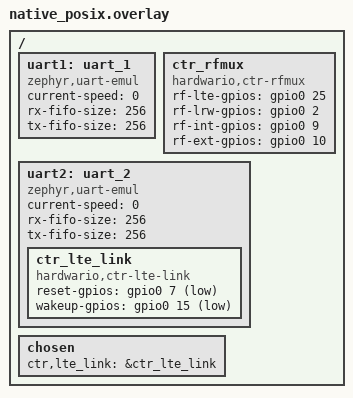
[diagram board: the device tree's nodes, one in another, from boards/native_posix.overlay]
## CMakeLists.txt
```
cmake_minimum_required(VERSION 3.20.0)

find_package(Zephyr REQUIRED HINTS $ENV{ZEPHYR_BASE})
project(test)

add_compile_definitions(CONFIG_CTR_RFMUX_LOG_LEVEL=4)
add_compile_definitions(CONFIG_CTR_LTE_LINK_LOG_LEVEL=3)

include_directories(${CMAKE_CURRENT_SOURCE_DIR}/../../../subsys/ctr_lte_v2)

target_sources(app PRIVATE src/mock_ctr_rfmux.c)
target_sources(app PRIVATE src/mock_ctr_lte_link.c)
target_sources(app PRIVATE src/mock_ctr_rtc.c)
target_sources(app PRIVATE src/mock_ctr_info.c)

target_sources_ifdef(CONFIG_TEST_FEATURE_PARSING app PRIVATE src/test_parse.c)
target_sources_ifdef(CONFIG_TEST_FEATURE_STACK app PRIVATE src/test_stack.c)
```

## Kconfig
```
#
# Copyright (c) 2023 HARDWARIO a.s.
#
# SPDX-License-Identifier: LicenseRef-HARDWARIO-5-Clause
#

menu "Test Features"

config TEST_FEATURE_PARSING
	bool "TEST_FEATURE_PARSING"
	default n

config TEST_FEATURE_STACK
	bool "TEST_FEATURE_PARSING"
	default n
	select CTR_LTE_V2_GNSS

config TEST_FEATURE_STACK_OVERRIDES_CONFIG
	bool "TEST_FEATURE_STACK"
	default n
	select CTR_LTE_V2_GNSS
	select TEST_FEATURE_STACK

config CTR_LTE_V2_DEFAULT_BANDS
	string "LTE Bands for CTR_LTE_V2"
	default "2,4,5,8,12,13,17,18,19,20,25,26,28,66" if TEST_FEATURE_STACK_OVERRIDES_CONFIG

config CTR_LTE_V2_DEFAULT_NETWORK
	string "Default Network for CTR_LTE_V2"
	default "23003" if TEST_FEATURE_STACK_OVERRIDES_CONFIG

config CTR_LTE_V2_DEFAULT_APN
	string "Default APN for CTR_LTE_V2"
	default "hardwario" if TEST_FEATURE_STACK_OVERRIDES_CONFIG

config CTR_LTE_V2_DEFAULT_ADDR
	string "Default Address for CTR_LTE_V2"
	default "46.101.214.168" if TEST_FEATURE_STACK_OVERRIDES_CONFIG

endmenu

#Include Zephyr's Kconfig
source "Kconfig"
```

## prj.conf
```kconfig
CONFIG_ZTEST=y
CONFIG_HEAP_MEM_POOL_SIZE=256
CONFIG_MAIN_STACK_SIZE=2048

CONFIG_LOG=y
CONFIG_LOG_FUNC_NAME_PREFIX_ERR=y
CONFIG_LOG_FUNC_NAME_PREFIX_WRN=y
CONFIG_LOG_FUNC_NAME_PREFIX_INF=y
CONFIG_LOG_FUNC_NAME_PREFIX_DBG=y

CONFIG_EVENTS=y

CONFIG_CTR_BUF=y
CONFIG_CTR_UTIL=y
CONFIG_CTR_CONFIG=y

CONFIG_CTR_LTE_V2=y
CONFIG_CTR_LTE_V2_LOG_LEVEL_DBG=y

CONFIG_SETTINGS=y

CONFIG_SHELL=y
CONFIG_SHELL_LOG_BACKEND=n
CONFIG_SHELL_BACKEND_SERIAL=y
CONFIG_SHELL_BACKEND_DUMMY=y
CONFIG_SHELL_CMD_BUFF_SIZE=90
CONFIG_SHELL_BACKEND_DUMMY_BUF_SIZE=4096

CONFIG_CBPRINTF_FP_SUPPORT=y

CONFIG_TEST_USERSPACE=y
CONFIG_GPIO=n
CONFIG_SERIAL=y
CONFIG_UART_NATIVE_PTY_0_ON_STDINOUT=y

CONFIG_HEAP_MEM_POOL_SIZE=8192

CONFIG_PM_DEVICE=y
CONFIG_REQUIRES_FULL_LIBC=y
CONFIG_RING_BUFFER=y
```

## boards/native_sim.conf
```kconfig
CONFIG_FLASH_SIMULATOR=y
CONFIG_FLASH=y
CONFIG_FLASH_MAP=y
```

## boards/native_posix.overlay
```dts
/ {

	uart1: uart_1 {
		compatible = "zephyr,uart-emul";
		status = "okay";
		current-speed = <0>;
		rx-fifo-size = <256>;
		tx-fifo-size = <256>;
	};

	ctr_rfmux: ctr_rfmux {
		compatible = "hardwario,ctr-rfmux";
		rf-lte-gpios = <&gpio0 25 GPIO_ACTIVE_HIGH>;
		rf-lrw-gpios = <&gpio0 2 GPIO_ACTIVE_HIGH>;
		rf-int-gpios = <&gpio0 9 GPIO_ACTIVE_HIGH>;
		rf-ext-gpios = <&gpio0 10 GPIO_ACTIVE_HIGH>;
	};

	uart2: uart_2 {
		compatible = "zephyr,uart-emul";
		status = "okay";
		current-speed = <0>;
		rx-fifo-size = <256>;
		tx-fifo-size = <256>;

		ctr_lte_link: ctr_lte_link {
			compatible = "hardwario,ctr-lte-link";
			status = "okay";
			reset-gpios = <&gpio0 7 (GPIO_ACTIVE_LOW | GPIO_OPEN_DRAIN)>;
			wakeup-gpios = <&gpio0 15 (GPIO_ACTIVE_LOW | GPIO_OPEN_DRAIN)>;
		};
	};
};

/ {
	chosen {
		ctr,lte_link = &ctr_lte_link;
	};
};
```

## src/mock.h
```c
#ifndef TESTS_SUBSYS_CTR_LTE_V2_SRC_MOCK_H_
#define TESTS_SUBSYS_CTR_LTE_V2_SRC_MOCK_H_

/* Zephyr includes */
#include <zephyr/kernel.h>

/* Standard includes */
#include <errno.h>
#include <stdarg.h>
#include <stdbool.h>
#include <stddef.h>
#include <stdint.h>
#include <stdio.h>
#include <string.h>

struct mock_link_item {
	const char *tx;
	const char *rx;
	const char *rx2;
	int delay_ms;
};

typedef char **list;

void mock_ctr_lte_link_start(struct mock_link_item *items, size_t count);

#endif
```

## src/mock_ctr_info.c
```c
#include <chester/ctr_info.h>

int ctr_info_get_vendor_name(char **vendor_name)
{
	static char name[] = "HARDWARIO";
	*vendor_name = name;
	return 0;
}

int ctr_info_get_product_name(char **product_name)
{
	static char name[] = "CHESTER-M";
	*product_name = name;
	return 0;
}

int ctr_info_get_hw_variant(char **hw_variant)
{
	static char variant[] = "CGLS";
	*hw_variant = variant;
	return 0;
}
int ctr_info_get_hw_revision(char **hw_revision)
{
	static char revision[] = "R3.2";
	*hw_revision = revision;
	return 0;
}

int ctr_info_get_fw_bundle(char **fw_bundle)
{
	static char bundle[] = "com.hardwario.mockup-app";
	*fw_bundle = bundle;
	return 0;
}

int ctr_info_get_fw_name(char **fw_name)
{
	static char name[] = "mockup-app";
	*fw_name = name;
	return 0;
}

int ctr_info_get_fw_version(char **fw_version)
{
	static char version[] = "v0.0.1";
	*fw_version = version;
	return 0;
}

int ctr_info_get_serial_number_uint32(uint32_t *serial_number)
{
	*serial_number = 2159017985;
	return 0;
}

int ctr_info_get_claim_token(char **claim_token)
{
	static char token[] = "98a8856ba6534bd5212176b22f3acbb3";
	*claim_token = token;
	return 0;
}

int ctr_info_get_ble_passkey(char **ble_passkey)
{
	static char passkey[] = "654123";
	*ble_passkey = passkey;
	return 0;
}

int ctr_info_get_product_family(enum ctr_info_product_family *product_family)
{
	*product_family = CTR_INFO_PRODUCT_FAMILY_CHESTER_M;
	return 0;
}
```

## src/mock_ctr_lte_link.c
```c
/*
 * Copyright (c) 2023 HARDWARIO a.s.
 *
 * SPDX-License-Identifier: LicenseRef-HARDWARIO-5-Clause
 */

#include "mock.h"
/* CHESTER includes */
#include <chester/drivers/ctr_lte_link.h>

/* Zephyr includes */
#include <zephyr/device.h>
#include <zephyr/devicetree.h>
#include <zephyr/kernel.h>
#include <zephyr/logging/log.h>
#include <zephyr/ztest.h>

/* Standard includes */
#include <errno.h>
#include <stdarg.h>
#include <stdbool.h>
#include <stddef.h>
#include <stdint.h>
#include <stdio.h>
#include <string.h>

#define DT_DRV_COMPAT hardwario_ctr_lte_link

LOG_MODULE_REGISTER(ctr_lte_link, LOG_LEVEL_INF);

#define RESET_DELAY   K_MSEC(100)
#define RESET_PAUSE   K_SECONDS(3)
#define WAKE_UP_DELAY K_MSEC(100)
#define WAKE_UP_PAUSE K_MSEC(100)
#define TX_GUARD_TIME K_MSEC(10)

#define TX_LINE_SUFFIX "\r\n"

#define TX_LINE_BUF_SIZE 1024
#define RX_LINE_BUF_SIZE 1024
#define RX_HEAP_MEM_SIZE 4096
#define RX_PIPE_BUF_SIZE 512
#define STACK_SIZE       1024
#define WORKQ_PRIORITY   K_PRIO_COOP(7)

struct ctr_lte_link_data {
	bool enabled;
	struct k_mutex lock;
	atomic_t in_dialog;
	atomic_t in_data_mode;
	atomic_t stop_request;
	char rx_line_buf[RX_LINE_BUF_SIZE];
	char tx_line_buf[TX_LINE_BUF_SIZE];
	const struct device *dev;
	ctr_lte_link_user_cb user_cb;
	void *user_data;
	struct k_work event_dispatch_work;
	struct k_work_delayable urc_dispatch_work;

	struct k_work_q workq;
	K_KERNEL_STACK_MEMBER(workq_stack, STACK_SIZE);
	struct k_fifo rx_fifo;
	struct k_heap rx_heap;
	uint8_t rx_heap_mem[RX_HEAP_MEM_SIZE];
	k_timepoint_t tx_timepoint;

	struct mock_link_item *items;
	size_t items_count;
	size_t items_index;

	const char *pending_rx_data;
	size_t pending_rx_data_len;
};

static inline struct ctr_lte_link_data *get_data(const struct device *dev)
{
	return dev->data;
}

static int ctr_lte_link_set_callback_(const struct device *dev, ctr_lte_link_user_cb user_cb,
				      void *user_data)
{

	k_mutex_lock(&get_data(dev)->lock, K_FOREVER);

	get_data(dev)->user_cb = user_cb;
	get_data(dev)->user_data = user_data;

	k_mutex_unlock(&get_data(dev)->lock);

	return 0;
}

static void ctr_lte_link_lock_(const struct device *dev)
{
	LOG_DBG("Lock");
	k_mutex_lock(&get_data(dev)->lock, K_FOREVER);
}

static void ctr_lte_link_unlock_(const struct device *dev)
{
	LOG_DBG("Unlock");
	k_mutex_unlock(&get_data(dev)->lock);
}

static int ctr_lte_link_reset_(const struct device *dev)
{

	LOG_DBG("Reset");
	k_sleep(RESET_DELAY);
	// k_sleep(RESET_PAUSE);
	return 0;
}

static int rx(const struct device *dev, const char line[])
{
	size_t len = strlen(line);

	struct ctr_lte_link_data *data = get_data(dev);

	char *p = k_heap_alloc(&data->rx_heap, len + 1, K_NO_WAIT);
	if (!p) {
		LOG_ERR("Call `k_heap_alloc` failed");
		if (data->user_cb) {
			data->user_cb(data->dev, CTR_LTE_LINK_EVENT_RX_LOSS, data->user_data);
		}

		return -ENOMEM;
	}

	LOG_DBG("Allocated from heap: %p - %u byte(s)", (void *)p, len + 1);

	strcpy(p, line);

	int ret = k_fifo_alloc_put(&data->rx_fifo, p);
	if (ret) {
		LOG_ERR("Call `k_fifo_alloc_put` failed: %d", ret);
		k_heap_free(&data->rx_heap, p);
		LOG_DBG("Released from heap: %p", (void *)p);
		return -ENOMEM;
	}

	if (data->user_cb && !atomic_get(&data->in_dialog)) {
		k_work_submit_to_queue(&data->workq, &data->event_dispatch_work);
	}

	return 0;
}

static void event_dispatch_work_handler(struct k_work *work)
{
	struct ctr_lte_link_data *const data =
		CONTAINER_OF(work, struct ctr_lte_link_data, event_dispatch_work);

	if (data->user_cb) {
		data->user_cb(data->dev, CTR_LTE_LINK_EVENT_RX_LINE, data->user_data);
	}
}

static void urc_dispatch_work_handler(struct k_work *work)
{
	struct ctr_lte_link_data *const data = CONTAINER_OF(
		(struct k_work_delayable *)work, struct ctr_lte_link_data, urc_dispatch_work);

	if (data->items_index < data->items_count) {
		const struct mock_link_item *item = &data->items[data->items_index];
		if (item->tx == NULL) {
			data->items_index++;
			if (item->rx) {
				rx(data->dev, item->rx);

				/* If URC starts with #XRECV:, store rx2 as pending data */
				if (strncmp(item->rx, "#XRECV:", 7) == 0 && item->rx2) {
					int expected_len = 0;
					sscanf(item->rx + 7, " %d", &expected_len);
					zassert_equal(
						(size_t)expected_len, strlen(item->rx2),
						"XRECV len mismatch: header says %d, data is %zu",
						expected_len, strlen(item->rx2));

					data->pending_rx_data = item->rx2;
					data->pending_rx_data_len = strlen(item->rx2);
				}
			}
			if (data->items_index < data->items_count) {
				item = &data->items[data->items_index];
				if (item->tx == NULL) {
					k_work_schedule(&data->urc_dispatch_work,
							K_MSEC(item->delay_ms));
				}
			}
		}
	}
}

static int ctr_lte_link_wake_up_(const struct device *dev)
{

	LOG_INF("Wake up");
	k_sleep(WAKE_UP_DELAY);
	// k_sleep(WAKE_UP_PAUSE);
	rx(dev, "Ready");
	return 0;
}

static int ctr_lte_link_enable_uart_(const struct device *dev)
{

	LOG_DBG("Enable UART");

	k_mutex_lock(&get_data(dev)->lock, K_FOREVER);

	if (get_data(dev)->enabled) {
		k_mutex_unlock(&get_data(dev)->lock);
		return 0;
	}

	atomic_set(&get_data(dev)->in_dialog, false);
	atomic_set(&get_data(dev)->in_data_mode, false);
	atomic_set(&get_data(dev)->stop_request, false);

	get_data(dev)->enabled = true;

	k_mutex_unlock(&get_data(dev)->lock);

	return 0;
}

static int ctr_lte_link_disable_uart_(const struct device *dev)
{

	LOG_DBG("Disable UART");

	k_mutex_lock(&get_data(dev)->lock, K_FOREVER);

	if (!get_data(dev)->enabled) {
		k_mutex_unlock(&get_data(dev)->lock);
		return 0;
	}

	get_data(dev)->enabled = false;

	k_mutex_unlock(&get_data(dev)->lock);

	return 0;
}

static int ctr_lte_link_enter_data_mode_(const struct device *dev)
{
	LOG_DBG("Enter data mode");

	k_mutex_lock(&get_data(dev)->lock, K_FOREVER);

	if (!get_data(dev)->enabled) {
		k_mutex_unlock(&get_data(dev)->lock);
		return -EBUSY;
	}

	atomic_set(&get_data(dev)->in_data_mode, true);

	k_mutex_unlock(&get_data(dev)->lock);

	return 0;
}

static int ctr_lte_link_exit_data_mode_(const struct device *dev)
{
	LOG_DBG("Exit data mode");

	k_mutex_lock(&get_data(dev)->lock, K_FOREVER);

	if (!get_data(dev)->enabled) {
		k_mutex_unlock(&get_data(dev)->lock);
		return -EBUSY;
	}

	atomic_set(&get_data(dev)->in_data_mode, false);

	k_mutex_unlock(&get_data(dev)->lock);

	return 0;
}

static int ctr_lte_link_enter_dialog_(const struct device *dev)
{
	LOG_DBG("Enter dialog");

	k_mutex_lock(&get_data(dev)->lock, K_FOREVER);

	if (!get_data(dev)->enabled) {
		k_mutex_unlock(&get_data(dev)->lock);
		return -EBUSY;
	}

	atomic_set(&get_data(dev)->in_dialog, true);

	k_mutex_unlock(&get_data(dev)->lock);

	return 0;
}

static int ctr_lte_link_exit_dialog_(const struct device *dev)
{
	LOG_DBG("Exit dialog");

	k_mutex_lock(&get_data(dev)->lock, K_FOREVER);

	if (!get_data(dev)->enabled) {
		k_mutex_unlock(&get_data(dev)->lock);
		return -EBUSY;
	}

	atomic_set(&get_data(dev)->in_dialog, false);

	k_mutex_unlock(&get_data(dev)->lock);

	return 0;
}

static int ctr_lte_link_send_line_(const struct device *dev, k_timeout_t timeout,
				   const char *format, va_list ap)
{

	struct ctr_lte_link_data *data = get_data(dev);

	k_mutex_lock(&data->lock, K_FOREVER);

	if (!data->enabled) {
		k_mutex_unlock(&data->lock);
		return -EBUSY;
	}

	if (data->in_data_mode) {
		k_mutex_unlock(&data->lock);
		return -EPERM;
	}

	// if (!sys_timepoint_expired(data->tx_timepoint)) {
	// 	k_sleep(sys_timepoint_timeout(data->tx_timepoint));
	// }

	size_t size = sizeof(data->tx_line_buf) - strlen(TX_LINE_SUFFIX);

	int ret = vsnprintf(data->tx_line_buf, size, format, ap);
	if (ret < 0) {
		LOG_ERR("Call `vsnprintf` failed: %d", ret);
		k_mutex_unlock(&data->lock);
		return -EINVAL;
	} else if (ret >= size) {
		LOG_ERR("Buffer too small");
		k_mutex_unlock(&data->lock);
		return -ENOBUFS;
	}

	LOG_INF("Send line: %s", data->tx_line_buf);

	// strcat(data->tx_line_buf, TX_LINE_SUFFIX);

	if (data->items_index < data->items_count) {
		const struct mock_link_item *item = &data->items[data->items_index];
		if (item->tx) {
			zassert_true(strcmp(data->tx_line_buf, item->tx) == 0,
				     "unexpected TX line: get %s, expected %s", data->tx_line_buf,
				     item->tx);

			data->items_index++;
			if (item->rx) {
				rx(dev, item->rx);
			}
			if (item->rx2) {
				rx(dev, item->rx2);
			}
			if (data->items_index < data->items_count) {
				item = &data->items[data->items_index];
				if (item->tx == NULL) {
					k_work_schedule(&data->urc_dispatch_work,
							K_MSEC(item->delay_ms));
				}
			}
		} else {
			LOG_ERR("Missing TX item %d", data->items_index);
		}
	}

	// if (strcmp(data->tx_line_buf, "AT") == 0) {
	// 	rx(dev, "OK");
	// }
	// if (strcmp(data->tx_line_buf, "AT+CGSN=1") == 0) {
	// 	rx(dev, "+CGSN: \"351358815178345\"");
	// 	rx(dev, "OK");
	// }

	// data->tx_timepoint = sys_timepoint_calc(TX_GUARD_TIME);

	k_mutex_unlock(&data->lock);

	return 0;
}

static int ctr_lte_link_recv_line_(const struct device *dev, k_timeout_t timeout, char **line)
{
	k_mutex_lock(&get_data(dev)->lock, K_FOREVER);

	if (get_data(dev)->in_data_mode) {
		k_mutex_unlock(&get_data(dev)->lock);
		return -EPERM;
	}

	*line = k_fifo_get(&get_data(dev)->rx_fifo, timeout);
	if (*line) {
		LOG_INF("Receive line: %s", *line);
	}

	k_mutex_unlock(&get_data(dev)->lock);

	return 0;
}

static int ctr_lte_link_free_line_(const struct device *dev, char *line)
{

	k_mutex_lock(&get_data(dev)->lock, K_FOREVER);

	k_heap_free(&get_data(dev)->rx_heap, line);
	LOG_DBG("Released from heap: %p", (void *)line);

	k_mutex_unlock(&get_data(dev)->lock);

	return 0;
}

static int ctr_lte_link_send_data_(const struct device *dev, k_timeout_t timeout, const void *buf,
				   size_t len)
{

	k_mutex_lock(&get_data(dev)->lock, K_FOREVER);

	if (!get_data(dev)->enabled) {
		k_mutex_unlock(&get_data(dev)->lock);
		return -EBUSY;
	}

	if (!get_data(dev)->in_data_mode) {
		k_mutex_unlock(&get_data(dev)->lock);
		return -EPERM;
	}

	k_mutex_unlock(&get_data(dev)->lock);

	return 0;
}

static int ctr_lte_link_recv_data_(const struct device *dev, k_timeout_t timeout, void *buf,
				   size_t size, size_t *len)
{
	struct ctr_lte_link_data *data = get_data(dev);

	LOG_INF("size: %d pending: %d", size, data->pending_rx_data_len);

	k_mutex_lock(&data->lock, K_FOREVER);

	if (!data->enabled) {
		k_mutex_unlock(&data->lock);
		return -EBUSY;
	}

	if (!data->in_data_mode) {
		k_mutex_unlock(&data->lock);
		return -EPERM;
	}

	*len = 0;

	if (data->pending_rx_data && data->pending_rx_data_len > 0) {
		size_t copy_len = data->pending_rx_data_len;
		if (copy_len > size) {
			copy_len = size;
		}
		memcpy(buf, data->pending_rx_data, copy_len);
		*len = copy_len;

		data->pending_rx_data = NULL;
		data->pending_rx_data_len = 0;
		rx(dev, "OK"); // Simulate OK after XRECV data is read
	}

	k_mutex_unlock(&data->lock);

	return 0;
}

static int ctr_lte_link_drv_init(const struct device *dev)
{
	struct ctr_lte_link_data *data = get_data(dev);
	k_mutex_init(&data->lock);
	k_fifo_init(&data->rx_fifo);
	k_heap_init(&data->rx_heap, data->rx_heap_mem, RX_HEAP_MEM_SIZE);

	struct k_work_queue_config cfg = {
		.name = "ctr_lte_link_drv_workq",
	};

	k_work_queue_start(&data->workq, data->workq_stack,
			   K_THREAD_STACK_SIZEOF(data->workq_stack), WORKQ_PRIORITY, &cfg);

	k_work_init(&data->event_dispatch_work, event_dispatch_work_handler);
	k_work_init_delayable(&data->urc_dispatch_work, urc_dispatch_work_handler);
	return 0;
}

static const struct ctr_lte_link_driver_api ctr_lte_link_driver_api = {
	.set_callback = ctr_lte_link_set_callback_,
	.lock = ctr_lte_link_lock_,
	.unlock = ctr_lte_link_unlock_,
	.reset = ctr_lte_link_reset_,
	.wake_up = ctr_lte_link_wake_up_,
	.enable_uart = ctr_lte_link_enable_uart_,
	.disable_uart = ctr_lte_link_disable_uart_,
	.enter_dialog = ctr_lte_link_enter_dialog_,
	.exit_dialog = ctr_lte_link_exit_dialog_,
	.enter_data_mode = ctr_lte_link_enter_data_mode_,
	.exit_data_mode = ctr_lte_link_exit_data_mode_,
	.send_line = ctr_lte_link_send_line_,
	.recv_line = ctr_lte_link_recv_line_,
	.free_line = ctr_lte_link_free_line_,
	.send_data = ctr_lte_link_send_data_,
	.recv_data = ctr_lte_link_recv_data_,
};

#define CTR_LTE_LINK_INIT(n)                                                                       \
	static struct ctr_lte_link_data inst_##n##_data = {                                        \
		.dev = DEVICE_DT_INST_GET(n),                                                      \
	};                                                                                         \
	DEVICE_DT_INST_DEFINE(n, ctr_lte_link_drv_init, NULL, &inst_##n##_data, NULL, POST_KERNEL, \
			      CONFIG_SERIAL_INIT_PRIORITY, &ctr_lte_link_driver_api);

DT_INST_FOREACH_STATUS_OKAY(CTR_LTE_LINK_INIT)

void mock_ctr_lte_link_start(struct mock_link_item *items, size_t count)
{
	LOG_INF("Mock CTR LTE LINK start");

	const struct device *dev = DEVICE_DT_INST_GET(0);

	if (!device_is_ready(dev)) {
		LOG_ERR("Device is not ready");
		return;
	}

	struct ctr_lte_link_data *data = get_data(DEVICE_DT_INST_GET(0));

	k_mutex_lock(&data->lock, K_FOREVER);

	data->items = items;
	data->items_count = count;
	data->items_index = 0;

	k_mutex_unlock(&data->lock);
}
```

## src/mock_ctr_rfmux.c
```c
/*
 * Copyright (c) 2023 HARDWARIO a.s.
 *
 * SPDX-License-Identifier: LicenseRef-HARDWARIO-5-Clause
 */

/* CHESTER includes */
#include <chester/drivers/ctr_rfmux.h>

/* Zephyr includes */
#include <zephyr/devicetree.h>
#include <zephyr/drivers/gpio.h>
#include <zephyr/kernel.h>
#include <zephyr/logging/log.h>

/* Standard includes */
#include <stdbool.h>
#include <stddef.h>

#define DT_DRV_COMPAT hardwario_ctr_rfmux

LOG_MODULE_REGISTER(ctr_rfmux, CONFIG_CTR_RFMUX_LOG_LEVEL);

struct ctr_rfmux_data {
	const struct device *dev;
	struct k_sem lock;
	bool is_acquired;
};

static inline struct ctr_rfmux_data *get_data(const struct device *dev)
{
	return dev->data;
}

static int ctr_rfmux_acquire_(const struct device *dev)
{
	if (k_is_in_isr()) {
		return -EWOULDBLOCK;
	}

	k_sem_take(&get_data(dev)->lock, K_FOREVER);

	if (get_data(dev)->is_acquired) {
		k_sem_give(&get_data(dev)->lock);
		return -EBUSY;
	}

	get_data(dev)->is_acquired = true;

	k_sem_give(&get_data(dev)->lock);

	return 0;
}

static int ctr_rfmux_release_(const struct device *dev)
{
	if (k_is_in_isr()) {
		return -EWOULDBLOCK;
	}

	k_sem_take(&get_data(dev)->lock, K_FOREVER);

	if (!get_data(dev)->is_acquired) {
		k_sem_give(&get_data(dev)->lock);
		return -EACCES;
	}

	get_data(dev)->is_acquired = false;

	k_sem_give(&get_data(dev)->lock);

	return 0;
}

static int ctr_rfmux_set_interface_(const struct device *dev, enum ctr_rfmux_interface interface)
{

	if (k_is_in_isr()) {
		return -EWOULDBLOCK;
	}

	k_sem_take(&get_data(dev)->lock, K_FOREVER);

	if (!get_data(dev)->is_acquired) {
		k_sem_give(&get_data(dev)->lock);
		return -EACCES;
	}

	k_sem_give(&get_data(dev)->lock);

	return 0;
}

static int ctr_rfmux_set_antenna_(const struct device *dev, enum ctr_rfmux_antenna antenna)
{

	if (k_is_in_isr()) {
		return -EWOULDBLOCK;
	}

	k_sem_take(&get_data(dev)->lock, K_FOREVER);

	if (!get_data(dev)->is_acquired) {
		k_sem_give(&get_data(dev)->lock);
		return -EACCES;
	}

	k_sem_give(&get_data(dev)->lock);

	return 0;
}

static int ctr_rfmux_init(const struct device *dev)
{

	k_sem_give(&get_data(dev)->lock);

	return 0;
}

static const struct ctr_rfmux_driver_api ctr_rfmux_driver_api = {
	.acquire = ctr_rfmux_acquire_,
	.release = ctr_rfmux_release_,
	.set_interface = ctr_rfmux_set_interface_,
	.set_antenna = ctr_rfmux_set_antenna_,
};

#define CTR_RFMUX_INIT(n)                                                                          \
	static struct ctr_rfmux_data inst_##n##_data = {                                           \
		.dev = DEVICE_DT_INST_GET(n),                                                      \
		.lock = Z_SEM_INITIALIZER(inst_##n##_data.lock, 0, 1),                             \
	};                                                                                         \
	DEVICE_DT_INST_DEFINE(n, ctr_rfmux_init, NULL, &inst_##n##_data, NULL, POST_KERNEL,        \
			      CONFIG_KERNEL_INIT_PRIORITY_DEVICE, &ctr_rfmux_driver_api);

DT_INST_FOREACH_STATUS_OKAY(CTR_RFMUX_INIT)
```

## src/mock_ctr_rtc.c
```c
#include <chester/ctr_rtc.h>

static int64_t m_ts = 0;

int ctr_rtc_set_ts(int64_t ts)
{
	m_ts = ts;
	return 0;
}

int ctr_rtc_get_ts(int64_t *ts)
{
	*ts = m_ts;
	return 0;
}
```

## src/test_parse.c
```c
/** @file
 *  @brief ctr_lte_v2 parse test suite
 *
 */

/* west twister -p native_sim -c -i -j 1 --testsuite-root . -vv */

#include <zephyr/kernel.h>
#include <zephyr/ztest.h>

#include <chester/ctr_buf.h>
#include <ctr_lte_v2_parse.h>

ZTEST(parser, test_xsocket_set)
{
	struct xsocket_set_param param;
	int ret = ctr_lte_v2_parse_xsocket_set("0,2,17", &param);

	zassert_ok(ret, "ctr_lte_v2_parse_xsocket_set failed");
	zassert_equal(param.handle, 0, "handle not equal");
	zassert_equal(param.type, 2, "type not equal");
	zassert_equal(param.protocol, 17, "protocol not equal");
}

ZTEST(parser, test_xsocket_get)
{
	struct xsocket_get_param param;
	int ret = ctr_lte_v2_parse_xsocket_get("0,1,0,2,0", &param);

	zassert_ok(ret, "ctr_lte_v2_parse_xsocket_set failed");
	zassert_equal(param.handle, 0, "handle not equal");
	zassert_equal(param.family, 1, "family not equal");
	zassert_equal(param.role, 0, "role not equal");
	zassert_equal(param.type, 2, "type not equal");
	zassert_equal(param.cid, 0, "cid not equal");
}

ZTEST(parser, test_urc_cereg_5)
{
	struct ctr_lte_v2_cereg_param param;
	int ret = ctr_lte_v2_parse_urc_cereg(
		"5,\"AF66\",\"009DE067\",9,,,\"00000000\",\"00111000\"", &param);

	zassert_ok(ret, "ctr_lte_v2_parse_urc_cereg failed");
	zassert_equal(param.valid, true, "param.valid not true");
	zassert_equal(param.stat, 5, "param.stat not equal");
	zassert_true(strcmp(param.tac, "AF66") == 0, "param.tac not equal");
	zassert_equal(param.cid, 0x009DE067, "param.cid not equal");
	zassert_equal(param.act, 9, "param.act not equal");
	zassert_equal(param.cause_type, 0, "param.cause_type not equal");
	zassert_equal(param.reject_cause, 0, "param.reject_cause not equal");
	zassert_equal(param.active_time, 0, "param.active_time not equal");
	zassert_equal(param.periodic_tau_ext, 86400, "param.periodic_tau_ext not equal");
}

ZTEST(parser, test_urc_cereg_5_active_time)
{
	struct ctr_lte_v2_cereg_param param;
	int ret = ctr_lte_v2_parse_urc_cereg(
		"5,\"AF66\",\"009DE067\",9,,,\"00000101\",\"00111000\"", &param);

	zassert_ok(ret, "ctr_lte_v2_parse_urc_cereg failed");
	zassert_equal(param.valid, true, "param.valid not true");
	zassert_equal(param.stat, 5, "param.stat not equal");
	zassert_true(strcmp(param.tac, "AF66") == 0, "param.tac not equal");
	zassert_equal(param.cid, 0x009DE067, "param.cid not equal");
	zassert_equal(param.act, 9, "param.act not equal");
	zassert_equal(param.cause_type, 0, "param.cause_type not equal");
	zassert_equal(param.reject_cause, 0, "param.reject_cause not equal");
	zassert_equal(param.active_time, 10, "param.active_time not equal");
	zassert_equal(param.periodic_tau_ext, 86400, "param.periodic_tau_ext not equal");
}

ZTEST(parser, test_urc_cereg_5_psm_disabled)
{
	struct ctr_lte_v2_cereg_param param;
	int ret = ctr_lte_v2_parse_urc_cereg(
		"5,\"3866\",\"074FEB0C\",7,,,\"11100000\",\"11100000\"", &param);

	zassert_ok(ret, "ctr_lte_v2_parse_urc_cereg failed");
	zassert_equal(param.valid, true, "param.valid not true");
	zassert_equal(param.stat, 5, "param.stat not equal");
	zassert_true(strcmp(param.tac, "3866") == 0, "param.tac not equal");
	zassert_equal(param.cid, 0x074FEB0C, "param.cid not equal");
	zassert_equal(param.act, 7, "param.act not equal");
	zassert_equal(param.cause_type, 0, "param.cause_type not equal");
	zassert_equal(param.reject_cause, 0, "param.reject_cause not equal");
	zassert_equal(param.active_time, -1, "param.active_time not equal");
	zassert_equal(param.periodic_tau_ext, -1, "param.periodic_tau_ext not equal");
}

ZTEST(parser, test_urc_cereg_2)
{
	struct ctr_lte_v2_cereg_param param;
	int ret = ctr_lte_v2_parse_urc_cereg("2,\"B4DC\",\"000AE520\",9", &param);

	zassert_ok(ret, "ctr_lte_v2_parse_urc_cereg failed");
	zassert_equal(param.valid, true, "param.valid not true");
	zassert_equal(param.stat, 2, "param.stat not equal");
	zassert_true(strcmp(param.tac, "B4DC") == 0, "param.tac not equal");
	zassert_equal(param.cid, 0x000AE520, "param.cid not equal");
	zassert_equal(param.act, 9, "param.act not equal");
}

ZTEST(parser, test_urc_cereg_2_empty)
{
	struct ctr_lte_v2_cereg_param param;
	int ret = ctr_lte_v2_parse_urc_cereg("2", &param);

	zassert_ok(ret, "ctr_lte_v2_parse_urc_cereg failed");
	zassert_equal(param.valid, true, "param.valid not true");
	zassert_equal(param.stat, 2, "param.stat not equal");
	zassert_true(strcmp(param.tac, "") == 0, "param.tac not equal");
	zassert_equal(param.cid, 0, "param.cid not equal");
	zassert_equal(param.act, 0, "param.act not equal");
}

ZTEST(parser, test_urc_cereg_4)
{
	struct ctr_lte_v2_cereg_param param;
	int ret = ctr_lte_v2_parse_urc_cereg("4", &param);

	zassert_ok(ret, "ctr_lte_v2_parse_urc_cereg failed");
	zassert_equal(param.valid, true, "param.valid not true");
	zassert_equal(param.stat, 4, "param.stat not equal");
	zassert_true(strcmp(param.tac, "") == 0, "param.tac not equal");
	zassert_equal(param.cid, 0, "param.cid not equal");
	zassert_equal(param.act, 0, "param.act not equal");
}

ZTEST(parser, test_urc_xmodemsleep_1_89999825)
{
	int p1, p2;
	int ret = ctr_lte_v2_parse_urc_xmodemsleep("1,89999825", &p1, &p2);

	zassert_ok(ret, "ctr_lte_v2_parse_urc_xmodemsleep failed");
	zassert_equal(p1, 1, "p1 not equal");
	zassert_equal(p2, 89999825, "p2 not equal");
}

ZTEST(parser, test_urc_xmodemsleep_1_0)
{
	int p1, p2;
	int ret = ctr_lte_v2_parse_urc_xmodemsleep("1,0", &p1, &p2);

	zassert_ok(ret, "ctr_lte_v2_parse_urc_xmodemsleep failed");
	zassert_equal(p1, 1, "p1 not equal");
	zassert_equal(p2, 0, "p2 not equal");
}

ZTEST(parser, test_urc_xmodemsleep_4_0)
{
	int p1, p2;
	int ret = ctr_lte_v2_parse_urc_xmodemsleep("4,0", &p1, &p2);

	zassert_ok(ret, "ctr_lte_v2_parse_urc_xmodemsleep failed");
	zassert_equal(p1, 4, "p1 not equal");
	zassert_equal(p2, 0, "p2 not equal");
}

ZTEST(parser, test_urc_xmodemsleep_4)
{
	int p1, p2;
	int ret = ctr_lte_v2_parse_urc_xmodemsleep("4", &p1, &p2);

	zassert_ok(ret, "ctr_lte_v2_parse_urc_xmodemsleep failed");
	zassert_equal(p1, 4, "p1 not equal");
	zassert_equal(p2, 0, "p2 not equal");
}

ZTEST(parser, test_coneval)
{

	struct ctr_lte_v2_conn_param param;
	int ret = ctr_lte_v2_parse_coneval(
		"0,1,7,68,29,47,\"000AE520\",\"23003\",135,6447,20,0,0,14,2,1,99", &param);

	zassert_ok(ret, "ctr_lte_v2_parse_coneval failed");
	zassert_equal(param.valid, true, "param.valid not true");
	zassert_equal(param.result, 0, "param.result not equal"); // success
	zassert_equal(param.eest, 7, "param.eest not equal");     // energy_estimate
	zassert_equal(param.ecl, 0, "param.ecl not equal");
	zassert_equal(param.rsrp, -72, "param.rsrp not equal");
	zassert_equal(param.rsrq, -5, "param.rsrq not equal");
	zassert_equal(param.snr, 23, "param.snr not equal");
	zassert_equal(param.plmn, 23003, "param.plmn not equal");
	zassert_equal(param.cid, 0x000AE520, "param.cid not equal");
	zassert_equal(param.band, 20, "param.band not equal");
	zassert_equal(param.earfcn, 6447, "param.earfcn not equal");
}

ZTEST(parser, test_urc_xgps)
{
	struct ctr_lte_v2_gnss_update update;

	char line[] = "49.256683,17.699627,292.599670,5.468742,0.165512,73.682823,\"2024-06-27 "
		      "16:06:52\"";
	int ret = ctr_lte_v2_parse_urc_xgps(line, &update);

	zassert_ok(ret, "ctr_lte_v2_parse_urc_xgps failed");
	zassert_within((double)update.latitude, 49.256683, 0.000001, "update.latitude not equal");
	zassert_within((double)update.longitude, 17.699627, 0.000001, "update.longitude not equal");
	zassert_within((double)update.altitude, 292.599670, 0.000001, "update.altitude not equal");
	zassert_within((double)update.accuracy, 5.468742, 0.000001, "update.accuracy not equal");
	zassert_within((double)update.speed, 0.165512, 0.000001, "update.speed not equal");
	zassert_within((double)update.heading, 73.682823, 0.000001, "update.heading not equal");
	zassert_true(strcmp(update.datetime, "2024-06-27 16:06:52") == 0,
		     "update.datetime not equal");
}

ZTEST(parser, test_cgcont)
{
	struct cgdcont_param param;
	int ret = ctr_lte_v2_parse_cgcont("0,\"IP\",\"iot.1nce.net\",\"10.52.2.149\",0,0", &param);

	zassert_ok(ret, "ctr_lte_v2_parse_cgcont failed");
	zassert_equal(param.cid, 0, "param.cid not equal");
	zassert_true(strcmp(param.pdn_type, "IP") == 0, "param.pdn_type not equal");
	zassert_true(strcmp(param.apn, "iot.1nce.net") == 0, "param.apn not equal");
	zassert_true(strcmp(param.addr, "10.52.2.149") == 0, "param.addr not equal");
}

ZTEST_SUITE(parser, NULL, NULL, NULL, NULL, NULL);

// int main() {
//     // Testovací příklady
//     const char *test1 = "11100000"; // Očekávaný výsledek: deaktivováno (-1)
//     const char *test2 = "00000000"; // Očekávaný výsledek: 0 sekund
//     const char *test3 = "00000101"; // GPRS Timer 2: 5 * 2 = 10 sekund
//     const char *test4 = "00101001"; // GPRS Timer 2: 9 * 60 = 540 sekund (9 minut)
//     const char *test5 = "10000101"; // GPRS Timer 3: 5 * 30 = 150 sekund (2,5 minuty)
//     const char *test6 = "11001000"; // GPRS Timer 3: 8 * 320h = 2560 hodin
//     (deaktivováno?)

//     printf("GPRS Timer 2 - Test 1: %d\n", parse_gprs_timer(test1, 2));
//     printf("GPRS Timer 2 - Test 2: %d\n", parse_gprs_timer(test2, 2));
//     printf("GPRS Timer 2 - Test 3: %d\n", parse_gprs_timer(test3, 2));
//     printf("GPRS Timer 2 - Test 4: %d\n", parse_gprs_timer(test4, 2));

//     printf("GPRS Timer 3 - Test 5: %d\n", parse_gprs_timer(test5, 3));
//     printf("GPRS Timer 3 - Test 6: %d\n", parse_gprs_timer(test6, 3));

//     return 0;
// }
```

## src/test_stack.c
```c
/* west twister --testsuite-root . -c -i -v -p native_sim */
/* west build -b native_sim -- -DCONFIG_TEST_FEATURE_STACK=y && ./build/zephyr/zephyr.elf */

/*
 * Test cases (run sequentially, depend on each other):
 *
 * - test_attach:          Initial connection to network
 * - test_send_only:       Send without receive (RAI_LAST)
 * - test_send_recv:       Send and receive with PSM
 * - test_timeout_in_send: API timeout before CSCON=1
 * - test_timeout_in_recv: API timeout during data wait
 * - test_send_recv_no_psm: Send and receive without PSM (CFUN=4 shutdown)
 */

#include "mock.h"

#include <chester/ctr_lte_v2.h>

#include <zephyr/kernel.h>
#include <zephyr/shell/shell.h>
#include <zephyr/shell/shell_dummy.h>
#include <zephyr/ztest.h>
#include <zephyr/settings/settings.h>

#include "ctr_lte_v2_state.h"

/* clang-format off */
#define URC(ms, urc) { .rx=urc, .delay_ms=ms }
#define RX_DATA(ms, urc, data) { .rx=urc, .rx2=data, .delay_ms=ms }
/* clang-format on */

#define ASSERT_FSM_STATE(expected)                                                                 \
	zassert_equal(strcmp(ctr_lte_v2_get_state(), expected), 0,                                 \
		      "expected state " expected " but got: %s", ctr_lte_v2_get_state())

/* ========================================================================== */
/* Test: Attach                                                               */
/* ========================================================================== */

static void test_attach(void)
{
	/* clang-format off */
	static struct mock_link_item items[] = {
		{"AT", "OK"},
		{"AT+CGSN=1", "+CGSN: \"351358815178345\"", "OK"},
		{"AT%HWVERSION", "%HWVERSION: nRF9160 SICA B1A", "OK"},
		{"AT%SHORTSWVER", "%SHORTSWVER: nrf9160_1.3.2", "OK"},
		{"AT#XSLMVER", "#XSLMVER: \"2.5.2\",\"2.5.0-lte-5ccd2d4dd54c\"", "OK"},
		{"AT#XVERSION", "#XVERSION: \"v1.7.0\"", "OK"},
		{"AT+CFUN=0", "OK"},
		{"AT%XPOFWARN=1,30", "OK"},
		{"AT%XTEMPHIGHLVL=70", "OK"},
		{"AT%XTEMP=1", "OK"},
		{"AT%XSYSTEMMODE=1,1,1,1", "OK"},
		{"AT%XDATAPRFL=0", "OK"},
		#if IS_ENABLED(CONFIG_TEST_FEATURE_STACK_OVERRIDES_CONFIG)
		{"AT%XBANDLOCK=1,\"0000000000000000000000100000000000000000000000000000000000001011000011110001100010011010\"", "OK"},
		#else
		{"AT%XBANDLOCK=0", "OK"},
		#endif
		{"AT%XSIM=1", "OK"},
		{"AT%XNETTIME=1", "OK"},
		{"AT%MDMEV=1", "OK"},
		{"AT%REL14FEAT=1,1,1,1,0", "OK"},
		{"AT%RAI=1", "OK"},
		{"AT+CPSMS=1,,,\"00111000\",\"00000000\"", "OK"},
		{"AT+CEPPI=1", "OK"},
		{"AT+CEREG=5", "OK"},
		{"AT+CGEREP=1", "OK"},
		{"AT+CMEE=1", "OK"},
		{"AT+CNEC=24", "OK"},
		{"AT%XCOEX0=1,1,1565,1586", "OK"},
		{"AT+CSCON=1", "OK"},
		#if IS_ENABLED(CONFIG_TEST_FEATURE_STACK_OVERRIDES_CONFIG)
		{"AT+COPS=1,2,\"23003\"", "OK"},
		{"AT+CGDCONT=0,\"IP\",\"hardwario\"", "OK"},
		#else
		{"AT+COPS=0", "OK"},
		{"AT+CGDCONT=0,\"IP\"", "OK"},
		#endif
		{"AT+CGAUTH=0,0", "OK"},
		{"AT%XMODEMSLEEP=1,500,10240", "OK"},
		{"AT+CFUN=1", "%XMODEMSLEEP: 4", "OK"},
		URC(0, "%XMODEMSLEEP: 4,0"),
		URC(0, "+CEREG: 0"),
		URC(500, "+CEREG: 2,\"B4DC\",\"000AE520\",9"),
		URC(100, "%XSIM: 1"),
		{"AT+CIMI", "901288910017273", "OK"},
		{"AT+CIMI", "901288910017273", "OK"},
		{"AT%XICCID", "%XICCID: 89882390000262826558", "OK"},
		{"AT+CRSM=176,28539,0,0,12", "+CRSM: 144,0,\"FFFFFFFFFFFFFFFFFFFFFFFF\"", "OK"},
		URC(100, "+CSCON: 1"),
		URC(50, "+CEREG: 5,\"B4DC\",\"000AE520\",9,0,18,\"00000000\",\"00111000\""),
		{"AT+COPS?", "+COPS: 1,2,\"23003\",9", "OK"},
		{"AT+CEREG?", "+CEREG: 5,5,\"B4DC\",\"000AE520\",9,0,18,\"00000000\",\"00111000\"", "OK"},
		{"AT%XCBAND", "%XCBAND: 20", "OK"},
		{"AT+CEINFO?", "+CEINFO: 0,1,C,8,1,-79,21", "OK"},
		{"AT+CGATT?", "+CGATT: 1", "OK"},
		{"AT+CGACT?", "+CGACT: 0,1", "OK"},
		{"AT+CGDCONT?", "+CGDCONT: 0,\"IP\",\"hardwario\",\"172.28.0.139\",0,0", "OK"},
		{"AT#XSOCKET=1,2,0,0", "#XSOCKET: 0,2,17", "OK"},
		#if IS_ENABLED(CONFIG_TEST_FEATURE_STACK_OVERRIDES_CONFIG)
		{"AT#XCONNECT=\"46.101.214.168\",5003", "#XCONNECT: 1", "OK"},
		#else
		{"AT#XCONNECT=\"192.168.192.4\",5003", "#XCONNECT: 1", "OK"},
		#endif
		{"AT%CONEVAL", "%CONEVAL: 0,1,7,95,30,49,\"000AE520\",\"23003\",135,6447,20,0,0,-8,2,1,73", "OK"},
	};
	/* clang-format on */

	mock_ctr_lte_link_start(items, ARRAY_SIZE(items));

	ctr_lte_v2_enable();

	int ret = ctr_lte_v2_wait_for_connected(K_MSEC(6000));
	zassert_ok(ret, "ctr_lte_v2_wait_for_connected failed");

	k_sleep(K_MSEC(500));
}

/* ========================================================================== */
/* Test: Send only (no receive)                                               */
/* ========================================================================== */

static void test_send_only(void)
{
	ASSERT_FSM_STATE("ready");

	/* clang-format off */
	static struct mock_link_item items[] = {
		/* Flow check in sleep ready cscon=1 */
		{"AT+CFUN?", "+CFUN: 1", "OK"},
		{"AT+CEREG?", "+CEREG: 5,5,\"B4DC\",\"000AE520\",9,0,18,\"00000000\",\"00111000\"",
		 "OK"},
		{"AT+CGATT?", "+CGATT: 1", "OK"},
		{"AT+CGACT?", "+CGACT: 0,1", "OK"},
		{"AT#XSOCKET?", "#XSOCKET: 0,1,0,2,0", "OK"},
		{"AT#XSOCKETOPT=1,51", "OK"},  /* SO_RAI_LAST - send only, no response expected */
		{"AT#XSEND=\"hello\"", "#XSEND: 5", "OK"},
		{"AT#XSOCKETOPT=1,50", "OK"},  /* SO_RAI_NO_DATA - done sending */
		{"AT%CONEVAL",
		 "%CONEVAL: 0,1,7,95,30,49,\"000AE520\",\"23003\",135,6447,20,0,0,-8,2,1,73", "OK"},
		URC(100, "+CSCON: 0"),
		URC(0, "%XMODEMSLEEP: 1,89999999"),
		{"AT#XSLEEP=2", "OK"},
	};
	/* clang-format on */

	mock_ctr_lte_link_start(items, ARRAY_SIZE(items));

	struct ctr_lte_v2_send_recv_param param = {
		.send_buf = "hello",
		.send_len = 5,
		.send_as_string = true,
		.recv_buf = NULL,
		.timeout = K_SECONDS(10),
		.rai = true,
	};

	int ret = ctr_lte_v2_send_recv(&param);
	zassert_ok(ret, "send_only failed: %d", ret);

	k_sleep(K_MSEC(5000));

	ASSERT_FSM_STATE("sleep");
}

/* ========================================================================== */
/* Test: Send and receive                                                     */
/* ========================================================================== */

static void test_send_recv(void)
{
	ASSERT_FSM_STATE("sleep");

	/* clang-format off */
	static struct mock_link_item items[] = {
		/* Flow check in sleep state */
		{"AT+CFUN?", "+CFUN: 1", "OK"},
		{"AT+CEREG?", "+CEREG: 5,5,\"B4DC\",\"000AE520\",9,0,18,\"00000000\",\"00111000\"",
		 "OK"},
		{"AT+CGATT?", "+CGATT: 1", "OK"},
		{"AT+CGACT?", "+CGACT: 0,1", "OK"},
		{"AT#XSOCKET?", "#XSOCKET: 0,1,0,2,0", "OK"},
		/* Send state */
		{"AT#XSOCKETOPT=1,52", "OK"},  /* SO_RAI_ONE_RESP - expect response */
		{"AT#XSEND=\"Hello world\"", "#XSEND: 11", "OK"},
		URC(50, "%XMODEMSLEEP: 1,0"),
		URC(200, "%MDMEV: SEARCH STATUS 2"),
		URC(500, "+CSCON: 1"),
		/* Receive state */
		{"AT#XRECV=5"},
		RX_DATA(200, "#XRECV: 8", "Hi there"),
		{"AT#XSOCKETOPT=1,50", "OK"},  /* SO_RAI_NO_DATA - done */
		/* Coneval state */
		{"AT%CONEVAL",
		 "%CONEVAL: 0,1,7,95,30,49,\"000AE520\",\"23003\",135,6447,20,0,0,-8,2,1,73", "OK"},
		/* Ready state -> later goes to sleep */
		URC(5000, "+CSCON: 0"),
		URC(0, "%XMODEMSLEEP: 1,89999999"),
		{"AT#XSLEEP=2", "OK"},
	};
	/* clang-format on */

	mock_ctr_lte_link_start(items, ARRAY_SIZE(items));

	char recv_buf[20] = {0};
	size_t recv_len = 0;
	struct ctr_lte_v2_send_recv_param param = {
		.send_buf = "Hello world",
		.send_len = 11,
		.send_as_string = true,
		.recv_buf = recv_buf,
		.recv_size = sizeof(recv_buf),
		.recv_len = &recv_len,
		.timeout = K_SECONDS(10),
		.rai = true,
	};

	int ret = ctr_lte_v2_send_recv(&param);
	zassert_ok(ret, "send_recv failed: %d", ret);
	zassert_equal(recv_len, 8, "recv_len incorrect");
	zassert_mem_equal(recv_buf, "Hi there", recv_len, "recv_buf incorrect");

	k_sleep(K_MSEC(10000));

	ASSERT_FSM_STATE("sleep");
}

/* ========================================================================== */
/* Test: Timeout helper (shared logic for timeout tests)                      */
/* ========================================================================== */

static void test_timeout_helper(k_timeout_t timeout)
{
	ASSERT_FSM_STATE("sleep");

	/* clang-format off */
	static struct mock_link_item items[] = {
		/* Flow check in ready state */
		{"AT+CFUN?", "+CFUN: 1", "OK"},
		{"AT+CEREG?", "+CEREG: 5,5,\"B4DC\",\"000AE520\",9,0,18,\"00000000\",\"00111000\"",
		 "OK"},
		{"AT+CGATT?", "+CGATT: 1", "OK"},
		{"AT+CGACT?", "+CGACT: 0,1", "OK"},
		{"AT#XSOCKET?", "#XSOCKET: 0,1,0,2,0", "OK"},
		/* Send state */
		{"AT#XSOCKETOPT=1,52", "OK"},
		{"AT#XSEND=\"No response\"", "#XSEND: 11", "OK"},
		URC(50, "%XMODEMSLEEP: 1,0"),
		URC(200, "%MDMEV: SEARCH STATUS 2"),
		URC(400, "+CSCON: 1"),
		/* Receive state - modem returns ERROR after 5s */
		{"AT#XRECV=5"},
		URC(5000, "ERROR"),
		/* Error state - flow check */
		{"AT+CFUN?", "+CFUN: 1", "OK"},
		{"AT+CEREG?", "+CEREG: 5,5,\"B4DC\",\"000AE520\",9,0,18,\"00000000\",\"00111000\"",
		 "OK"},
		{"AT+CGATT?", "+CGATT: 1", "OK"},
		{"AT+CGACT?", "+CGACT: 0,1", "OK"},
		{"AT#XSOCKET?", "#XSOCKET: 0,1,0,2,0", "OK"},
		/* Error state timeout (5s) -> ready state -> sleep */
		URC(6000, "+CSCON: 0"),
		URC(0, "%XMODEMSLEEP: 1,89999999"),
		{"AT#XSLEEP=2", "OK"},
	};
	/* clang-format on */

	mock_ctr_lte_link_start(items, ARRAY_SIZE(items));

	char recv_buf[20] = {0};
	size_t recv_len = 0;
	struct ctr_lte_v2_send_recv_param param = {
		.send_buf = "No response",
		.send_len = 11,
		.send_as_string = true,
		.recv_buf = recv_buf,
		.recv_size = sizeof(recv_buf),
		.recv_len = &recv_len,
		.timeout = timeout,
		.rai = true,
	};

	int ret = ctr_lte_v2_send_recv(&param);
	zassert_equal(ret, -EIO, "expected -EIO but got: %d", ret);

	k_sleep(K_MSEC(15000));

	ASSERT_FSM_STATE("sleep");
}

/* Timeout in send state (before CSCON=1, ~650ms into sequence) */
static void test_timeout_in_send(void)
{
	test_timeout_helper(K_MSEC(300));
}

/* Timeout in receive state (after CSCON=1, waiting for data) */
static void test_timeout_in_recv(void)
{
	test_timeout_helper(K_MSEC(2000));
}

/* ========================================================================== */
/* Test: Send and receive (no PSM - network doesn't support PSM)              */
/* ========================================================================== */

static void test_send_recv_no_psm(void)
{
	ASSERT_FSM_STATE("sleep");

	/* clang-format off */
	static struct mock_link_item items[] = {
		/* Flow check in ready state */
		{"AT+CFUN?", "+CFUN: 1", "OK"},
		{"AT+CEREG?", "+CEREG: 5,5,\"B4DC\",\"000AE520\",9,0,18,\"00000000\",\"00111000\"",
		 "OK"},
		{"AT+CGATT?", "+CGATT: 1", "OK"},
		{"AT+CGACT?", "+CGACT: 0,1", "OK"},
		{"AT#XSOCKET?", "#XSOCKET: 0,1,0,2,0", "OK"},
		/* Send state */
		{"AT#XSOCKETOPT=1,52", "OK"},
		{"AT#XSEND=\"Hello no PSM\"", "#XSEND: 12", "OK"},
		/* Receive state */
		URC(50, "%XMODEMSLEEP: 1,0"),
		URC(200, "%MDMEV: SEARCH STATUS 2"),
		URC(200, "+CEREG: 5,\"05F2\",\"074FEB01\",7,,,\"11100000\",\"11100000\""),  /* PSM disabled */
		URC(400, "+CSCON: 1"),
		{"AT#XRECV=5"},
		RX_DATA(200, "#XRECV: 8", "Hi there"),
		{"AT#XSOCKETOPT=1,50", "OK"},
		/* Coneval state */
		{"AT%CONEVAL", "%CONEVAL: 0,1,7,62,11,27,\"074FEB01\",\"23002\",339,6300,20,0,0,3,1,1,94", "OK"},
		/* Ready state timeout -> no PSM, so CFUN=4 */
		{"AT#XSOCKET=0", "#XSOCKET: 0,\"closed\"", "OK"},
		{"AT+CFUN=4", "OK"},
		URC(0, "+CGEV: ME PDN DEACT 0"),
		URC(0, "+CEREG: 0"),
		URC(0, "+CGEV: ME DETACH"),
		URC(0, "+CSCON: 0"),
		URC(0, "%XSIM: 0"),
		URC(0, "%XMODEMSLEEP: 4"),
		{"AT#XSLEEP=2", "OK"},
	};
	/* clang-format on */

	mock_ctr_lte_link_start(items, ARRAY_SIZE(items));

	char recv_buf[20] = {0};
	size_t recv_len = 0;
	struct ctr_lte_v2_send_recv_param param = {
		.send_buf = "Hello no PSM",
		.send_len = 12,
		.send_as_string = true,
		.recv_buf = recv_buf,
		.recv_size = sizeof(recv_buf),
		.recv_len = &recv_len,
		.timeout = K_SECONDS(10),
		.rai = true,
	};

	int ret = ctr_lte_v2_send_recv(&param);
	zassert_ok(ret, "send_recv_no_psm failed: %d", ret);
	zassert_equal(recv_len, 8, "recv_len incorrect");
	zassert_mem_equal(recv_buf, "Hi there", recv_len, "recv_buf incorrect");

	k_sleep(K_MSEC(10000));

	ASSERT_FSM_STATE("sleep");
}

/* ========================================================================== */
/* Main test - runs all subtests sequentially (they depend on each other)     */
/* ========================================================================== */

ZTEST(stack, test_full_sequence)
{
	test_attach();
	test_send_only();
	test_send_recv();
	test_timeout_in_send();
	test_timeout_in_recv();
	test_send_recv_no_psm();
}

ZTEST_SUITE(stack, NULL, NULL, NULL, NULL, NULL);
```
